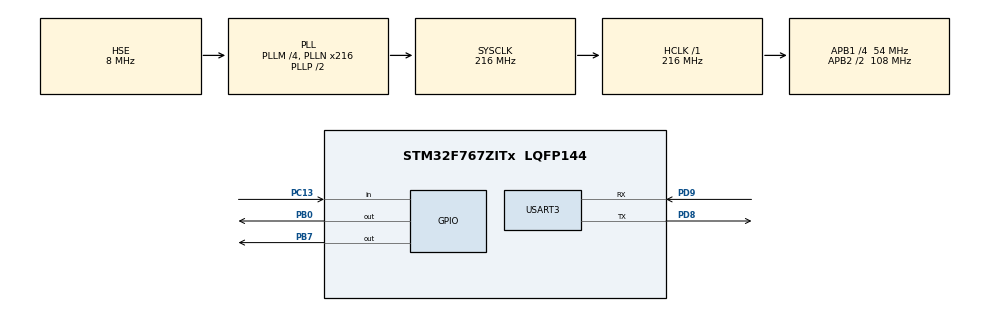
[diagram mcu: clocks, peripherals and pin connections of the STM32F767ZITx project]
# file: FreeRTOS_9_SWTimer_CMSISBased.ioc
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FREERTOS.INCLUDE_vTaskDelayUntil=1
FREERTOS.Tasks01=normalTask_uart,0,128,start_normalTask_uart,Default,NULL,Dynamic,NULL,NULL;normalTask_led,0,128,start_normalTask_led,Default,NULL,Dynamic,NULL,NULL
FREERTOS.Timers01=periodicTimer,callback_periodicTimer,osTimerPeriodic,Default,NULL,Dynamic,NULL;onceTimer,callback_onceTimer,osTimerOnce,Default,NULL,Dynamic,NULL
FREERTOS.configTIMER_TASK_PRIORITY=6
FREERTOS.configUSE_COUNTING_SEMAPHORES=0
FREERTOS.configUSE_NEWLIB_REENTRANT=1
FREERTOS.configUSE_TIMERS=1
Mcu.Family=STM32F7
Mcu.Name=STM32F767ZITx
Mcu.Package=LQFP144
NVIC.PriorityGroup=NVIC_PRIORITYGROUP_4
NVIC.TIM6_DAC_IRQn=true\:15\:0\:false\:false\:true\:false\:false\:true\:true
NVIC.TimeBase=TIM6_DAC_IRQn
NVIC.TimeBaseIP=TIM6
NVIC.USART3_IRQn=true\:5\:0\:false\:false\:true\:true\:true\:true\:true
PB0.Signal=GPIO_Output
PB7.Signal=GPIO_Output
PC13.Signal=GPIO_Input
PD8.Mode=Asynchronous
PD8.Signal=USART3_TX
PD9.Mode=Asynchronous
PD9.Signal=USART3_RX
PH0/OSC_IN.Mode=HSE-External-Oscillator
PH0/OSC_IN.Signal=RCC_OSC_IN
PH1/OSC_OUT.Mode=HSE-External-Oscillator
PH1/OSC_OUT.Signal=RCC_OSC_OUT
ProjectManager.HeapSize=0x200
ProjectManager.StackSize=0x400
ProjectManager.TargetToolchain=STM32CubeIDE
RCC.AHBFreq_Value=216000000
RCC.APB1CLKDivider=RCC_HCLK_DIV4
RCC.APB1Freq_Value=54000000
RCC.APB1TimFreq_Value=108000000
RCC.APB2CLKDivider=RCC_HCLK_DIV2
RCC.APB2Freq_Value=108000000
RCC.APB2TimFreq_Value=216000000
RCC.CortexFreq_Value=216000000
RCC.HCLKFreq_Value=216000000
RCC.HSE_VALUE=8000000
RCC.HSI_VALUE=16000000
RCC.LSE_VALUE=32768
RCC.PLLM=4
RCC.PLLN=216
RCC.PLLSourceVirtual=RCC_PLLSOURCE_HSE
RCC.SYSCLKFreq_VALUE=216000000
RCC.SYSCLKSource=RCC_SYSCLKSOURCE_PLLCLK
RCC.USBFreq_Value=216000000
RCC.VCOOutputFreq_Value=432000000
USART3.VirtualMode-Asynchronous=VM_ASYNC
VP_FREERTOS_VS_CMSIS_V1.Mode=CMSIS_V1
VP_SYS_VS_tim6.Mode=TIM6
board=custom

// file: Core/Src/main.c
/* USER CODE BEGIN Header */
/**
  ******************************************************************************
  * @file           : main.c
  * @brief          : Main program body
  ******************************************************************************
  * @author			: Jabed-Akhtar (GitHub)
  * @date			: 11.10.2022
  ******************************************************************************
  * Description:
  * 	- a source within this script: https://youtube.com/playlist?list=PLfIJKC1ud8gj1t2y36sabPT4YcKzmN_5D
  * 	- Related doc/file can be found at location '<project-dir>/zz_docs/...'
  *
  * @attention
  *
  ******************************************************************************
  */
/* USER CODE END Header */
#include "main.h"
#include "cmsis_os.h"

/* USER CODE BEGIN Includes */

#include <stdio.h>
#include "stdlib.h"
#include <string.h>

/* USER CODE END Includes */

UART_HandleTypeDef huart3;

osThreadId normalTask_uartHandle;
osThreadId normalTask_ledHandle;
osTimerId periodicTimerHandle;
osTimerId onceTimerHandle;

void SystemClock_Config(void);
static void MX_GPIO_Init(void);
static void MX_USART3_UART_Init(void);
void start_normalTask_uart(void const * argument);
void start_normalTask_led(void const * argument);
void callback_periodicTimer(void const * argument);
void callback_onceTimer(void const * argument);

int main(void)
{

  /* MCU Configuration--------------------------------------------------------*/

  /* Reset of all peripherals, Initializes the Flash interface and the Systick. */
  HAL_Init();

  /* Configure the system clock */
  SystemClock_Config();

  /* Initialize all configured peripherals */
  MX_GPIO_Init();
  MX_USART3_UART_Init();
  /* USER CODE BEGIN 2 */

  // sending data through USART at the beginning of Programm
  char stri[] = "\n---------- Programm started!!! ----------\n\n\r";
  HAL_UART_Transmit(&huart3, (uint8_t*)stri, strlen(stri), HAL_MAX_DELAY); //HAL_MAX_DELAY -> 0xFFFFFFFFU

  /* USER CODE END 2 */

  /* Create the timer(s) */
  /* definition and creation of periodicTimer */
  osTimerDef(periodicTimer, callback_periodicTimer);
  periodicTimerHandle = osTimerCreate(osTimer(periodicTimer), osTimerPeriodic, NULL);

  /* definition and creation of onceTimer */
  osTimerDef(onceTimer, callback_onceTimer);
  onceTimerHandle = osTimerCreate(osTimer(onceTimer), osTimerOnce, NULL);

  /* Create the thread(s) */
  /* definition and creation of normalTask_uart */
  osThreadDef(normalTask_uart, start_normalTask_uart, osPriorityNormal, 0, 128);
  normalTask_uartHandle = osThreadCreate(osThread(normalTask_uart), NULL);

  /* definition and creation of normalTask_led */
  osThreadDef(normalTask_led, start_normalTask_led, osPriorityNormal, 0, 128);
  normalTask_ledHandle = osThreadCreate(osThread(normalTask_led), NULL);

  /* Start scheduler */
  osKernelStart();

  /* We should never get here as control is now taken by the scheduler */
  /* Infinite loop */
  while (1)
  {

  }
}

void SystemClock_Config(void)
{
  RCC_OscInitTypeDef RCC_OscInitStruct = {0};
  RCC_ClkInitTypeDef RCC_ClkInitStruct = {0};

  /** Configure the main internal regulator output voltage
  */
  __HAL_RCC_PWR_CLK_ENABLE();
  __HAL_PWR_VOLTAGESCALING_CONFIG(PWR_REGULATOR_VOLTAGE_SCALE1);

  /** Initializes the RCC Oscillators according to the specified parameters
  * in the RCC_OscInitTypeDef structure.
  */
  RCC_OscInitStruct.OscillatorType = RCC_OSCILLATORTYPE_HSE;
  RCC_OscInitStruct.HSEState = RCC_HSE_ON;
  RCC_OscInitStruct.PLL.PLLState = RCC_PLL_ON;
  RCC_OscInitStruct.PLL.PLLSource = RCC_PLLSOURCE_HSE;
  RCC_OscInitStruct.PLL.PLLM = 4;
  RCC_OscInitStruct.PLL.PLLN = 216;
  RCC_OscInitStruct.PLL.PLLP = RCC_PLLP_DIV2;
  RCC_OscInitStruct.PLL.PLLQ = 2;
  RCC_OscInitStruct.PLL.PLLR = 2;
  if (HAL_RCC_OscConfig(&RCC_OscInitStruct) != HAL_OK)
  {
    Error_Handler();
  }

  /** Activate the Over-Drive mode
  */
  if (HAL_PWREx_EnableOverDrive() != HAL_OK)
  {
    Error_Handler();
  }

  /** Initializes the CPU, AHB and APB buses clocks
  */
  RCC_ClkInitStruct.ClockType = RCC_CLOCKTYPE_HCLK|RCC_CLOCKTYPE_SYSCLK
                              |RCC_CLOCKTYPE_PCLK1|RCC_CLOCKTYPE_PCLK2;
  RCC_ClkInitStruct.SYSCLKSource = RCC_SYSCLKSOURCE_PLLCLK;
  RCC_ClkInitStruct.AHBCLKDivider = RCC_SYSCLK_DIV1;
  RCC_ClkInitStruct.APB1CLKDivider = RCC_HCLK_DIV4;
  RCC_ClkInitStruct.APB2CLKDivider = RCC_HCLK_DIV2;

  if (HAL_RCC_ClockConfig(&RCC_ClkInitStruct, FLASH_LATENCY_7) != HAL_OK)
  {
    Error_Handler();
  }
}

static void MX_USART3_UART_Init(void)
{

  huart3.Instance = USART3;
  huart3.Init.BaudRate = 115200;
  huart3.Init.WordLength = UART_WORDLENGTH_8B;
  huart3.Init.StopBits = UART_STOPBITS_1;
  huart3.Init.Parity = UART_PARITY_NONE;
  huart3.Init.Mode = UART_MODE_TX_RX;
  huart3.Init.HwFlowCtl = UART_HWCONTROL_NONE;
  huart3.Init.OverSampling = UART_OVERSAMPLING_16;
  huart3.Init.OneBitSampling = UART_ONE_BIT_SAMPLE_DISABLE;
  huart3.AdvancedInit.AdvFeatureInit = UART_ADVFEATURE_NO_INIT;
  if (HAL_UART_Init(&huart3) != HAL_OK)
  {
    Error_Handler();
  }

}

static void MX_GPIO_Init(void)
{
  GPIO_InitTypeDef GPIO_InitStruct = {0};

  /* GPIO Ports Clock Enable */
  __HAL_RCC_GPIOC_CLK_ENABLE();
  __HAL_RCC_GPIOH_CLK_ENABLE();
  __HAL_RCC_GPIOB_CLK_ENABLE();
  __HAL_RCC_GPIOD_CLK_ENABLE();

  /*Configure GPIO pin Output Level */
  HAL_GPIO_WritePin(GPIOB, GPIO_PIN_0|GPIO_PIN_7, GPIO_PIN_RESET);

  /*Configure GPIO pin : PC13 */
  GPIO_InitStruct.Pin = GPIO_PIN_13;
  GPIO_InitStruct.Mode = GPIO_MODE_INPUT;
  GPIO_InitStruct.Pull = GPIO_NOPULL;
  HAL_GPIO_Init(GPIOC, &GPIO_InitStruct);

  /*Configure GPIO pins : PB0 PB7 */
  GPIO_InitStruct.Pin = GPIO_PIN_0|GPIO_PIN_7;
  GPIO_InitStruct.Mode = GPIO_MODE_OUTPUT_PP;
  GPIO_InitStruct.Pull = GPIO_NOPULL;
  GPIO_InitStruct.Speed = GPIO_SPEED_FREQ_LOW;
  HAL_GPIO_Init(GPIOB, &GPIO_InitStruct);

}

void start_normalTask_uart(void const * argument)
{
  /* USER CODE BEGIN 5 */

  osTimerStart(periodicTimerHandle, 1000); // 1000 ms
  /* Infinite loop */
  for(;;)
  {
	  HAL_UART_Transmit(&huart3, (uint8_t *)"Sending from UART Task.\n", 23, 100);
      osDelay(2000);
  }
  /* USER CODE END 5 */
}

void start_normalTask_led(void const * argument)
{
  /* USER CODE BEGIN start_normalTask_led */
  /* Infinite loop */
  for(;;)
  {
	  if (HAL_GPIO_ReadPin(GPIOC, GPIO_PIN_13)) // if the button is pressed
	  {
		  HAL_GPIO_WritePin(GPIOB, GPIO_PIN_0, 1); // set the LED
		  osTimerStart(onceTimerHandle, 4000);
	  }

      osDelay(20);
  }
  /* USER CODE END start_normalTask_led */
}

/* callback_periodicTimer function */
void callback_periodicTimer(void const * argument)
{
  /* USER CODE BEGIN callback_periodicTimer */

	HAL_UART_Transmit(&huart3, (uint8_t *)"\nSending from PERIODIC Timer.\n", 30, 100);

  /* USER CODE END callback_periodicTimer */
}

/* callback_onceTimer function */
void callback_onceTimer(void const * argument)
{
  /* USER CODE BEGIN callback_onceTimer */

	HAL_GPIO_WritePin(GPIOB, GPIO_PIN_0, 0); // Reset the LED

  /* USER CODE END callback_onceTimer */
}

void HAL_TIM_PeriodElapsedCallback(TIM_HandleTypeDef *htim)
{
  if (htim->Instance == TIM6) {
    HAL_IncTick();
  }
}

void Error_Handler(void)
{
  __disable_irq();
  while (1)
  {
  }
}

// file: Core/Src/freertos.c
/* USER CODE BEGIN Header */
/**
  ******************************************************************************
  * File Name          : freertos.c
  * Description        : Code for freertos applications
  ******************************************************************************
  * @attention
  *
  * Copyright (c) 2022 STMicroelectronics.
  * All rights reserved.
  *
  * This software is licensed under terms that can be found in the LICENSE file
  * in the root directory of this software component.
  * If no LICENSE file comes with this software, it is provided AS-IS.
  *
  ******************************************************************************
  */
/* USER CODE END Header */

#include "FreeRTOS.h"
#include "task.h"
#include "main.h"

/* GetIdleTaskMemory prototype (linked to static allocation support) */
void vApplicationGetIdleTaskMemory( StaticTask_t **ppxIdleTaskTCBBuffer, StackType_t **ppxIdleTaskStackBuffer, uint32_t *pulIdleTaskStackSize );

/* GetTimerTaskMemory prototype (linked to static allocation support) */
void vApplicationGetTimerTaskMemory( StaticTask_t **ppxTimerTaskTCBBuffer, StackType_t **ppxTimerTaskStackBuffer, uint32_t *pulTimerTaskStackSize );

/* USER CODE BEGIN GET_IDLE_TASK_MEMORY */
static StaticTask_t xIdleTaskTCBBuffer;
static StackType_t xIdleStack[configMINIMAL_STACK_SIZE];

void vApplicationGetIdleTaskMemory( StaticTask_t **ppxIdleTaskTCBBuffer, StackType_t **ppxIdleTaskStackBuffer, uint32_t *pulIdleTaskStackSize )
{
  *ppxIdleTaskTCBBuffer = &xIdleTaskTCBBuffer;
  *ppxIdleTaskStackBuffer = &xIdleStack[0];
  *pulIdleTaskStackSize = configMINIMAL_STACK_SIZE;
  /* place for user code */
}
/* USER CODE END GET_IDLE_TASK_MEMORY */

/* USER CODE BEGIN GET_TIMER_TASK_MEMORY */
static StaticTask_t xTimerTaskTCBBuffer;
static StackType_t xTimerStack[configTIMER_TASK_STACK_DEPTH];

void vApplicationGetTimerTaskMemory( StaticTask_t **ppxTimerTaskTCBBuffer, StackType_t **ppxTimerTaskStackBuffer, uint32_t *pulTimerTaskStackSize )
{
  *ppxTimerTaskTCBBuffer = &xTimerTaskTCBBuffer;
  *ppxTimerTaskStackBuffer = &xTimerStack[0];
  *pulTimerTaskStackSize = configTIMER_TASK_STACK_DEPTH;
  /* place for user code */
}
/* USER CODE END GET_TIMER_TASK_MEMORY */
